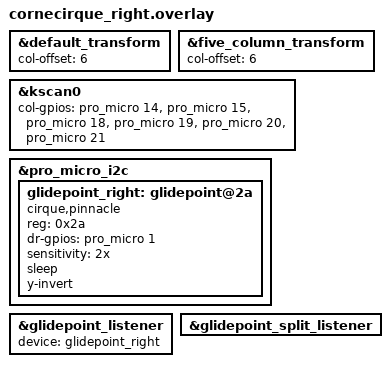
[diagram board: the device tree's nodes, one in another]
/*
 * Copyright (c) 2020 Pete Johanson
 *
 * SPDX-License-Identifier: MIT
 */

#include "cornecirque.dtsi"

&default_transform {
    col-offset = <6>;
};

&five_column_transform {
    col-offset = <6>;
};

&kscan0 {
    col-gpios
        = <&pro_micro 14 GPIO_ACTIVE_HIGH>
        , <&pro_micro 15 GPIO_ACTIVE_HIGH>
        , <&pro_micro 18 GPIO_ACTIVE_HIGH>
        , <&pro_micro 19 GPIO_ACTIVE_HIGH>
        , <&pro_micro 20 GPIO_ACTIVE_HIGH>
        , <&pro_micro 21 GPIO_ACTIVE_HIGH>
        ;
};

&pro_micro_i2c {
    status = "okay";

    glidepoint_right: glidepoint@2a {
        compatible = "cirque,pinnacle";
        reg = <0x2a>;
        status = "okay";
        dr-gpios = <&pro_micro 1 (GPIO_ACTIVE_HIGH)>;
        // TRACKPAD EXACTAMENTE COMO FABRICA — 7-sep-2026, tarde.
        // El cursor dejo de moverse (los taps si llegaban) con la config de la
        // manana. Con el firmware de fabrica del 1-sep volvio a moverse, asi que
        // estas dos lineas vuelven a su valor original y NO se tocan hasta saber
        // si el trackpad aguanta. Lo que cambia respecto a la manana:
        //   sensitivity: era "3x"  -> vuelve a "2x"
        //   sleep:       se habia quitado -> vuelve a estar puesto
        sensitivity = "2x";
        sleep;
        //no-taps;
        y-invert;
        //x-invert;
        //scroll;
    };
};

&glidepoint_listener {
    status = "okay";
    device = <&glidepoint_right>;
};

&glidepoint_split_listener {
    status = "okay";
};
